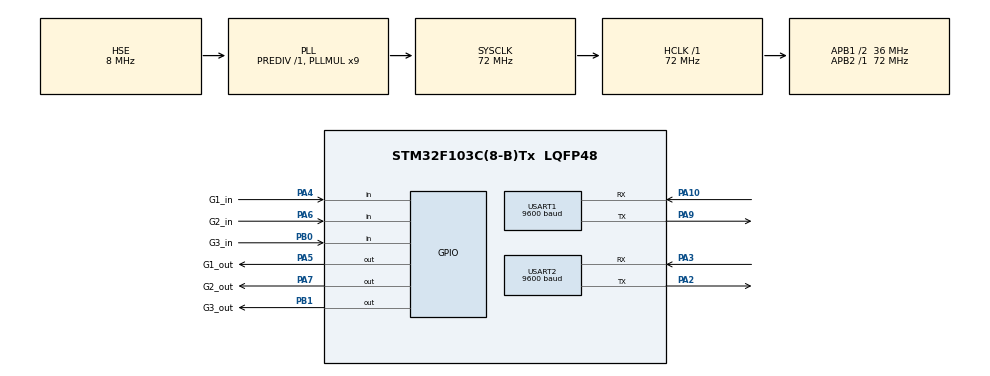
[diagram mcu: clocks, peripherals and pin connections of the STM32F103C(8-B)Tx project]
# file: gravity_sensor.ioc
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Dma.Request0=USART1_RX
Dma.Request1=USART1_TX
Dma.Request2=USART2_RX
Dma.Request3=USART2_TX
Dma.USART1_RX.0.Direction=DMA_PERIPH_TO_MEMORY
Dma.USART1_RX.0.Instance=DMA1_Channel5
Dma.USART1_RX.0.MemDataAlignment=DMA_MDATAALIGN_BYTE
Dma.USART1_RX.0.MemInc=DMA_MINC_ENABLE
Dma.USART1_RX.0.Mode=DMA_NORMAL
Dma.USART1_RX.0.PeriphDataAlignment=DMA_PDATAALIGN_BYTE
Dma.USART1_RX.0.PeriphInc=DMA_PINC_DISABLE
Dma.USART1_RX.0.Priority=DMA_PRIORITY_LOW
Dma.USART1_TX.1.Direction=DMA_MEMORY_TO_PERIPH
Dma.USART1_TX.1.Instance=DMA1_Channel4
Dma.USART1_TX.1.MemDataAlignment=DMA_MDATAALIGN_BYTE
Dma.USART1_TX.1.MemInc=DMA_MINC_ENABLE
Dma.USART1_TX.1.Mode=DMA_NORMAL
Dma.USART1_TX.1.PeriphDataAlignment=DMA_PDATAALIGN_BYTE
Dma.USART1_TX.1.PeriphInc=DMA_PINC_DISABLE
Dma.USART1_TX.1.Priority=DMA_PRIORITY_LOW
Dma.USART2_RX.2.Direction=DMA_PERIPH_TO_MEMORY
Dma.USART2_RX.2.Instance=DMA1_Channel6
Dma.USART2_RX.2.MemDataAlignment=DMA_MDATAALIGN_BYTE
Dma.USART2_RX.2.MemInc=DMA_MINC_ENABLE
Dma.USART2_RX.2.Mode=DMA_NORMAL
Dma.USART2_RX.2.PeriphDataAlignment=DMA_PDATAALIGN_BYTE
Dma.USART2_RX.2.PeriphInc=DMA_PINC_DISABLE
Dma.USART2_RX.2.Priority=DMA_PRIORITY_LOW
Dma.USART2_TX.3.Direction=DMA_MEMORY_TO_PERIPH
Dma.USART2_TX.3.Instance=DMA1_Channel7
Dma.USART2_TX.3.MemDataAlignment=DMA_MDATAALIGN_BYTE
Dma.USART2_TX.3.MemInc=DMA_MINC_ENABLE
Dma.USART2_TX.3.Mode=DMA_NORMAL
Dma.USART2_TX.3.PeriphDataAlignment=DMA_PDATAALIGN_BYTE
Dma.USART2_TX.3.PeriphInc=DMA_PINC_DISABLE
Dma.USART2_TX.3.Priority=DMA_PRIORITY_LOW
FREERTOS.INCLUDE_vTaskDelayUntil=1
FREERTOS.Tasks01=defaultTask,0,128,StartDefaultTask,Default,NULL
Mcu.Family=STM32F1
Mcu.Name=STM32F103C(8-B)Tx
Mcu.Package=LQFP48
NVIC.DMA1_Channel4_IRQn=true\:5\:0\:false\:false\:true\:true\:false\:true
NVIC.DMA1_Channel5_IRQn=true\:5\:0\:false\:false\:true\:true\:false\:true
NVIC.DMA1_Channel6_IRQn=true\:5\:0\:false\:false\:true\:true\:false\:true
NVIC.DMA1_Channel7_IRQn=true\:5\:0\:false\:false\:true\:true\:false\:true
NVIC.PriorityGroup=NVIC_PRIORITYGROUP_4
NVIC.TIM1_UP_IRQn=true\:0\:0\:false\:false\:true\:false\:false\:true
NVIC.TimeBase=TIM1_UP_IRQn
NVIC.TimeBaseIP=TIM1
NVIC.USART1_IRQn=true\:5\:0\:false\:false\:true\:true\:true\:true
NVIC.USART2_IRQn=true\:5\:0\:false\:false\:true\:true\:true\:true
PA10.Mode=Asynchronous
PA10.Signal=USART1_RX
PA13.Mode=Serial_Wire
PA13.Signal=SYS_JTMS-SWDIO
PA14.Mode=Serial_Wire
PA14.Signal=SYS_JTCK-SWCLK
PA2.Mode=Asynchronous
PA2.Signal=USART2_TX
PA3.Mode=Asynchronous
PA3.Signal=USART2_RX
PA4.GPIO_Label=G1_in
PA4.Signal=GPIO_Input
PA5.GPIO_Label=G1_out
PA5.Signal=GPIO_Output
PA6.GPIO_Label=G2_in
PA6.Signal=GPIO_Input
PA7.GPIO_Label=G2_out
PA7.Signal=GPIO_Output
PA9.Mode=Asynchronous
PA9.Signal=USART1_TX
PB0.GPIO_Label=G3_in
PB0.Signal=GPIO_Input
PB1.GPIO_Label=G3_out
PB1.Signal=GPIO_Output
PD0-OSC_IN.Mode=HSE-External-Oscillator
PD0-OSC_IN.Signal=RCC_OSC_IN
PD1-OSC_OUT.Mode=HSE-External-Oscillator
PD1-OSC_OUT.Signal=RCC_OSC_OUT
ProjectManager.HeapSize=0x200
ProjectManager.StackSize=0x400
ProjectManager.TargetToolchain=MDK-ARM V5.27
RCC.AHBFreq_Value=72000000
RCC.APB1CLKDivider=RCC_HCLK_DIV2
RCC.APB1Freq_Value=36000000
RCC.APB1TimFreq_Value=72000000
RCC.APB2Freq_Value=72000000
RCC.APB2TimFreq_Value=72000000
RCC.HCLKFreq_Value=72000000
RCC.PLLMUL=RCC_PLL_MUL9
RCC.PLLSourceVirtual=RCC_PLLSOURCE_HSE
RCC.SYSCLKFreq_VALUE=72000000
RCC.SYSCLKSource=RCC_SYSCLKSOURCE_PLLCLK
RCC.USBFreq_Value=72000000
USART1.BaudRate=9600
USART1.VirtualMode=VM_ASYNC
USART2.BaudRate=9600
USART2.VirtualMode=VM_ASYNC
VP_FREERTOS_VS_CMSIS_V1.Mode=CMSIS_V1
VP_SYS_VS_tim1.Mode=TIM1
board=custom

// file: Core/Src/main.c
/* USER CODE BEGIN Header */
/**
  ******************************************************************************
  * @file           : main.c
  * @brief          : Main program body
  ******************************************************************************
  * @attention
  *
  * <h2><center>&copy; Copyright (c) 2020 STMicroelectronics.
  * All rights reserved.</center></h2>
  *
  * This software component is licensed by ST under BSD 3-Clause license,
  * the "License"; You may not use this file except in compliance with the
  * License. You may obtain a copy of the License at:
  *                        opensource.org/licenses/BSD-3-Clause
  *
  ******************************************************************************
  */
/* USER CODE END Header */

#include "main.h"
#include "cmsis_os.h"

/* USER CODE BEGIN Includes */
#include "System_task.h"
#include "Uart.h"
/* USER CODE END Includes */

UART_HandleTypeDef huart1;
UART_HandleTypeDef huart2;
DMA_HandleTypeDef hdma_usart1_rx;
DMA_HandleTypeDef hdma_usart1_tx;
DMA_HandleTypeDef hdma_usart2_rx;
DMA_HandleTypeDef hdma_usart2_tx;

osThreadId defaultTaskHandle;

void SystemClock_Config(void);
static void MX_GPIO_Init(void);
static void MX_USART1_UART_Init(void);
static void MX_USART2_UART_Init(void);
static void MX_DMA_Init(void);
void StartDefaultTask(void const * argument);

int main(void)
{

  /* MCU Configuration--------------------------------------------------------*/

  /* Reset of all peripherals, Initializes the Flash interface and the Systick. */
  HAL_Init();

  /* Configure the system clock */
  SystemClock_Config();

  /* Initialize all configured peripherals */
  MX_GPIO_Init();
  MX_USART1_UART_Init();
  MX_USART2_UART_Init();
  MX_DMA_Init();

  /* Create the thread(s) */
  /* definition and creation of defaultTask */
  osThreadDef(defaultTask, StartDefaultTask, osPriorityNormal, 0, 128);
  defaultTaskHandle = osThreadCreate(osThread(defaultTask), NULL);

  /* Start scheduler */
  osKernelStart();

  /* We should never get here as control is now taken by the scheduler */

  /* Infinite loop */
  while (1)
  {

  }
}

void SystemClock_Config(void)
{
  RCC_OscInitTypeDef RCC_OscInitStruct = {0};
  RCC_ClkInitTypeDef RCC_ClkInitStruct = {0};

  /** Initializes the CPU, AHB and APB busses clocks
  */
  RCC_OscInitStruct.OscillatorType = RCC_OSCILLATORTYPE_HSE;
  RCC_OscInitStruct.HSEState = RCC_HSE_ON;
  RCC_OscInitStruct.HSEPredivValue = RCC_HSE_PREDIV_DIV1;
  RCC_OscInitStruct.HSIState = RCC_HSI_ON;
  RCC_OscInitStruct.PLL.PLLState = RCC_PLL_ON;
  RCC_OscInitStruct.PLL.PLLSource = RCC_PLLSOURCE_HSE;
  RCC_OscInitStruct.PLL.PLLMUL = RCC_PLL_MUL9;
  if (HAL_RCC_OscConfig(&RCC_OscInitStruct) != HAL_OK)
  {
    Error_Handler();
  }
  /** Initializes the CPU, AHB and APB busses clocks
  */
  RCC_ClkInitStruct.ClockType = RCC_CLOCKTYPE_HCLK|RCC_CLOCKTYPE_SYSCLK
                              |RCC_CLOCKTYPE_PCLK1|RCC_CLOCKTYPE_PCLK2;
  RCC_ClkInitStruct.SYSCLKSource = RCC_SYSCLKSOURCE_PLLCLK;
  RCC_ClkInitStruct.AHBCLKDivider = RCC_SYSCLK_DIV1;
  RCC_ClkInitStruct.APB1CLKDivider = RCC_HCLK_DIV2;
  RCC_ClkInitStruct.APB2CLKDivider = RCC_HCLK_DIV1;

  if (HAL_RCC_ClockConfig(&RCC_ClkInitStruct, FLASH_LATENCY_2) != HAL_OK)
  {
    Error_Handler();
  }
}

static void MX_USART1_UART_Init(void)
{

  huart1.Instance = USART1;
  huart1.Init.BaudRate = 9600;
  huart1.Init.WordLength = UART_WORDLENGTH_8B;
  huart1.Init.StopBits = UART_STOPBITS_1;
  huart1.Init.Parity = UART_PARITY_NONE;
  huart1.Init.Mode = UART_MODE_TX_RX;
  huart1.Init.HwFlowCtl = UART_HWCONTROL_NONE;
  huart1.Init.OverSampling = UART_OVERSAMPLING_16;
  if (HAL_UART_Init(&huart1) != HAL_OK)
  {
    Error_Handler();
  }

}

static void MX_USART2_UART_Init(void)
{

  huart2.Instance = USART2;
  huart2.Init.BaudRate = 9600;
  huart2.Init.WordLength = UART_WORDLENGTH_8B;
  huart2.Init.StopBits = UART_STOPBITS_1;
  huart2.Init.Parity = UART_PARITY_NONE;
  huart2.Init.Mode = UART_MODE_TX_RX;
  huart2.Init.HwFlowCtl = UART_HWCONTROL_NONE;
  huart2.Init.OverSampling = UART_OVERSAMPLING_16;
  if (HAL_UART_Init(&huart2) != HAL_OK)
  {
    Error_Handler();
  }

}

static void MX_DMA_Init(void)
{

  /* DMA controller clock enable */
  __HAL_RCC_DMA1_CLK_ENABLE();

  /* DMA interrupt init */
  /* DMA1_Channel4_IRQn interrupt configuration */
  HAL_NVIC_SetPriority(DMA1_Channel4_IRQn, 5, 0);
  HAL_NVIC_EnableIRQ(DMA1_Channel4_IRQn);
  /* DMA1_Channel5_IRQn interrupt configuration */
  HAL_NVIC_SetPriority(DMA1_Channel5_IRQn, 5, 0);
  HAL_NVIC_EnableIRQ(DMA1_Channel5_IRQn);
  /* DMA1_Channel6_IRQn interrupt configuration */
  HAL_NVIC_SetPriority(DMA1_Channel6_IRQn, 5, 0);
  HAL_NVIC_EnableIRQ(DMA1_Channel6_IRQn);
  /* DMA1_Channel7_IRQn interrupt configuration */
  HAL_NVIC_SetPriority(DMA1_Channel7_IRQn, 5, 0);
  HAL_NVIC_EnableIRQ(DMA1_Channel7_IRQn);

}

static void MX_GPIO_Init(void)
{
  GPIO_InitTypeDef GPIO_InitStruct = {0};

  /* GPIO Ports Clock Enable */
  __HAL_RCC_GPIOD_CLK_ENABLE();
  __HAL_RCC_GPIOA_CLK_ENABLE();
  __HAL_RCC_GPIOB_CLK_ENABLE();

  /*Configure GPIO pin Output Level */
  HAL_GPIO_WritePin(GPIOA, G1_out_Pin|G2_out_Pin, GPIO_PIN_RESET);

  /*Configure GPIO pin Output Level */
  HAL_GPIO_WritePin(G3_out_GPIO_Port, G3_out_Pin, GPIO_PIN_RESET);

  /*Configure GPIO pins : G1_in_Pin G2_in_Pin */
  GPIO_InitStruct.Pin = G1_in_Pin|G2_in_Pin;
  GPIO_InitStruct.Mode = GPIO_MODE_INPUT;
  GPIO_InitStruct.Pull = GPIO_NOPULL;
  HAL_GPIO_Init(GPIOA, &GPIO_InitStruct);

  /*Configure GPIO pins : G1_out_Pin G2_out_Pin */
  GPIO_InitStruct.Pin = G1_out_Pin|G2_out_Pin;
  GPIO_InitStruct.Mode = GPIO_MODE_OUTPUT_PP;
  GPIO_InitStruct.Pull = GPIO_NOPULL;
  GPIO_InitStruct.Speed = GPIO_SPEED_FREQ_LOW;
  HAL_GPIO_Init(GPIOA, &GPIO_InitStruct);

  /*Configure GPIO pin : G3_in_Pin */
  GPIO_InitStruct.Pin = G3_in_Pin;
  GPIO_InitStruct.Mode = GPIO_MODE_INPUT;
  GPIO_InitStruct.Pull = GPIO_NOPULL;
  HAL_GPIO_Init(G3_in_GPIO_Port, &GPIO_InitStruct);

  /*Configure GPIO pin : G3_out_Pin */
  GPIO_InitStruct.Pin = G3_out_Pin;
  GPIO_InitStruct.Mode = GPIO_MODE_OUTPUT_PP;
  GPIO_InitStruct.Pull = GPIO_NOPULL;
  GPIO_InitStruct.Speed = GPIO_SPEED_FREQ_LOW;
  HAL_GPIO_Init(G3_out_GPIO_Port, &GPIO_InitStruct);

}

void StartDefaultTask(void const * argument)
{
  /* USER CODE BEGIN 5 */
  /* Infinite loop */
  for(;;)
  {
    System_Tasks_Init(); //�����ʼ��

		osThreadTerminate (defaultTaskHandle);  //ɾ����������
  }
  /* USER CODE END 5 */
}

void HAL_TIM_PeriodElapsedCallback(TIM_HandleTypeDef *htim)
{
  if (htim->Instance == TIM1) {
    HAL_IncTick();
  }
}

void Error_Handler(void)
{
}

/************************ (C) COPYRIGHT STMicroelectronics *****END OF FILE****/
